# MSP430FR2475 register map
Vendor: msp430gen; File version: v0.4.0-28-gb0087ce-dirty
Registers are 16-bit, read-write, reset 0x0 unless marked. A register's access mark holds for its fields unless they carry their own. Offsets are from the block's base; [hi:lo] are bit positions; lines under a group give offsets from that group; {n}, {i} and the like mark numbered series; 'fields as' and 'values as' point back to an identical list.

## BAKMEM
Base 0x00000660
0x00 BAKMEM0 — Backup Memory registers. Backup Memory 0.
{0x0+2i} BAKMEM{i} (i=1..9) — Backup Memory {i}.
0x14 BAKMEM10 — Backup Memory registers. Backup Memory 10.
{0x0+2i} BAKMEM{i} (i=11..15) — Backup Memory {i}.

## E_COMP0
Base 0x000008E0
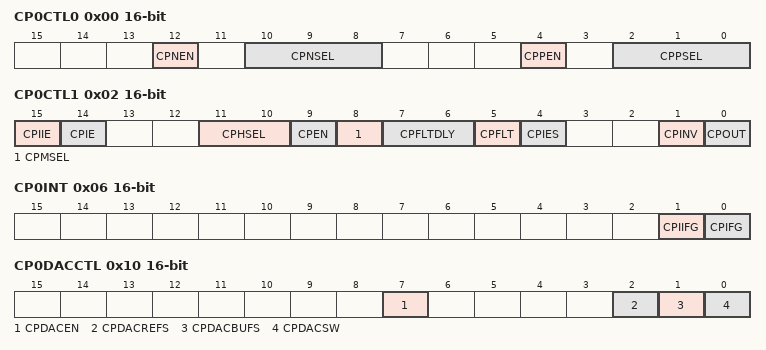
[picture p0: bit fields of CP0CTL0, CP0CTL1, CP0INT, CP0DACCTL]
0x00 CP0CTL0 — Comparator Control Register 0
  [12] CPNEN — Channel input enable for the - terminal
    0=Selected analog input channel for V- terminal is disabled; 1=Selected analog input channel for V- terminal is enabled
  [10:8] CPNSEL — Channel input selected for the - terminal
    {v}=select external input source (v=0..3); 4=device specific, please refer to device data sheet for details; 5=device specific, please refer to device data sheet for details; 6=6-bit DAC
  [4] CPPEN — Channel input enable for the V+ terminal
    0=Selected analog input channel for V+ terminal is disabled; 1=Selected analog input channel for V+ terminal is enabled
  [2:0] CPPSEL — Channel input selected for the V+ terminal
    values as CPNSEL
0x02 CP0CTL1 — Comparator Control Register 1
  [15] CPIIE — Comparator inverted interrupt output enable bit
    0=Interrupt inverted output is disabled; 1=Interrupt inverted output is enabled
  [14] CPIE — Comparator interrupt output enable bit
    0=Interrupt output is disabled; 1=Interrupt output is enabled
  [11:10] CPHSEL — Programable Hysteresis mode. These bits are used to select the Hysteresis mode.
    0=disable; 1=10mV; 2=20mV; 3=30mV
  [9] CPEN — Comparator enable/disable. This bit is used to disable/enable the comparator. When the comparator is disabled, the Comparator consumes no power.
    0=Comparator is disabled; 1=Comparator is enabled
  [8] CPMSEL — Power mode selection.
    0=High-power & High speed mode (500nA); 1=Low-power & Low speed mode (10nA)
  [7:6] CPFLTDLY — Analog Filter Delay selection. These bits are used to select the analog filter delay
    0=Typical filter delay of 450ns; 1=Typical filter delay of 900ns; 2=Typical filter delay of 1800ns; 3=Typical filter delay of 3600ns
  [5] CPFLT — Analog Output Low Pass filter Selection. Changing CPFLT might set interrupt flag.
    0=Comparator output is not filtered; 1=Comparator output is filtered
  [4] CPIES — Interrupt edge select for CEIIFG and CEIFG
    0=Rising edge for CPIFG, falling edge for CPIIFG; 1=Falling edge for CPIFG, rising edge for CPIIFG
  [1] CPINV — Comparator output polarity
    0=Comparator output is non-inverted; 1=Comparator output is inverted
  [0] CPOUT ro — Comparator output value
0x06 CP0INT — Comparator Interrupt Control Register
  [1] CPIIFG — Comparator output inverted interrupt flag
    0=No interrupt pending; 1=Output interrupt pending
  [0] CPIFG — Comparator output interrupt flag
    0=No interrupt pending; 1=Output interrupt pending
0x08 CP0IV — Comparator Interrupt Vector Word Register
  [15:0] CPIV ro — Comparator interrupt vector word register
    0=NONE (No interrupt pending); 2=CPIFG; 4=CPIIFG
0x10 CP0DACCTL — 6-bit Comparator built-in DAC Control Register
  [7] CPDACEN — Comparator built-in DAC output control bit.
    0=DAC output is disabled; 1=DAC output is enabled
  [2] CPDACREFS — Comparator built-in DAC reference voltage selection
    0=VDD selected; 1=on-chip VREF selected
  [1] CPDACBUFS — Comparator built-in DAC buffer controlled source selection.
    0=Comparator output is selected as the buffer control source; 1=CPDACSW bit is selected as the buffer control source
  [0] CPDACSW — This bit is only valid when CPDACBUFS is set to 1.
    0=CPDACBUF1 selected; 1=CPDACBUF2 selected
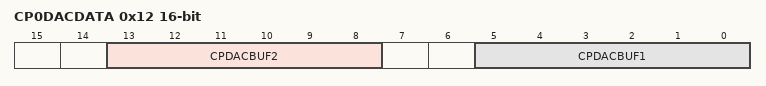
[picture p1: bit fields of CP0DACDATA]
0x12 CP0DACDATA — 6-bit Comparator built-in DAC Data Register
  [13:8] CPDACBUF2 — 2nd 6-bit DAC buffer Data
    0=0v; {v}=selected reference voltage * {v}/64 (v=1..63)
  [5:0] CPDACBUF1 — 1st 6-bit DAC buffer Data
    0=0v; {v}=selected reference voltage * {v}/64 (v=1..8); 9=selected reference voltage *9/64; {v}=selected reference voltage * {v}/64 (v=10..63)

## TLV — Device descriptors (TLV)
Base 0x00001A00
0x00 INFO_LENGTH 8-bit ro
0x01 CRC_LENGTH 8-bit ro
0x02 CRC_VALUE ro — CRC value of the descriptors from 1A04h to 1AF7h (CRC-CCITT)
0x04 DEVICE_ID ro
{0x4+i} CRC_DATA[{i}] (i=0..243) 8-bit ro — Bytes 1A04h to 1AF7h, the range the CRC value covers
0x06 HW_REVISION 8-bit ro — Hardware revision
0x07 FW_REVISION 8-bit ro — Firmware revision
0x08 DIE_RECORD_TAG 8-bit ro
0x09 DIE_RECORD_LENGTH 8-bit ro
0x0A LOT_WAFER_ID 32-bit ro
0x0E DIE_X_POSITION ro
0x10 DIE_Y_POSITION ro
0x12 TEST_RESULT ro
0x14 ADC_CAL_TAG 8-bit ro — ADC calibration tag
0x15 ADC_CAL_LENGTH 8-bit ro — ADC calibration length
0x16 ADC_GAIN_FACTOR ro
0x18 ADC_OFFSET ro
{0x1A+4i} ADC_TEMP_CAL[{i}] (i=0..2) group — Temperature sensor calibration with the 1.5 V, 2.0 V or 2.5 V reference (index 0, 1 or 2)
  0x00 TEMP_30C ro — Temperature sensor ADC result at 30 degrees C
  0x02 TEMP_HIGH ro — Temperature sensor ADC result at 105 degrees C
0x26 REF_CAL_TAG 8-bit ro — REF calibration tag
0x27 REF_CAL_LENGTH 8-bit ro — REF calibration length
{0x28+2i} REF_FACTOR[{i}] (i=0..2) ro — Factor of the 1.5 V, 2.0 V or 2.5 V reference (index 0, 1 or 2)
0x2E DCO_TAP_16MHZ ro — DCO tap setting for 16 MHz
